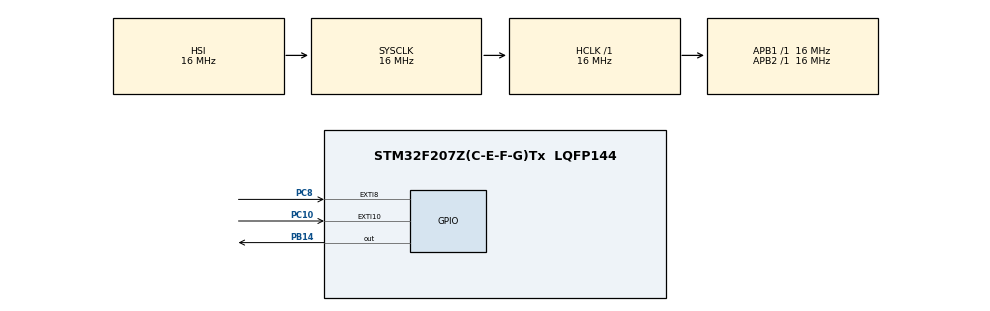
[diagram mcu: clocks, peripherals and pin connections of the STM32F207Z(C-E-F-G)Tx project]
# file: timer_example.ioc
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Mcu.Family=STM32F2
Mcu.Name=STM32F207Z(C-E-F-G)Tx
Mcu.Package=LQFP144
NVIC.EXTI15_10_IRQn=true\:0\:0\:false\:false\:true\:true\:true\:true
NVIC.EXTI9_5_IRQn=true\:0\:0\:false\:false\:true\:true\:true\:true
NVIC.PriorityGroup=NVIC_PRIORITYGROUP_4
NVIC.TIM1_CC_IRQn=true\:0\:0\:false\:false\:true\:true\:true\:true
NVIC.TIM1_UP_TIM10_IRQn=true\:0\:0\:false\:false\:true\:true\:true\:true
PB14.Signal=GPIO_Output
PC10.GPIO_ModeDefaultEXTI=GPIO_MODE_IT_FALLING
PC10.GPIO_PuPd=GPIO_PULLDOWN
PC10.Signal=GPXTI10
PC8.GPIO_ModeDefaultEXTI=GPIO_MODE_IT_RISING
PC8.GPIO_PuPd=GPIO_PULLDOWN
PC8.Signal=GPXTI8
ProjectManager.HeapSize=0x200
ProjectManager.StackSize=0x400
ProjectManager.TargetToolchain=STM32CubeIDE
RCC.48MHZClocksFreq_Value=48000000
RCC.AHBFreq_Value=16000000
RCC.APB1Freq_Value=16000000
RCC.APB2Freq_Value=16000000
RCC.CortexFreq_Value=16000000
RCC.HSE_VALUE=25000000
RCC.HSI_VALUE=16000000
RCC.LSE_VALUE=32768
RCC.SYSCLKFreq_VALUE=16000000
RCC.VCOOutputFreq_Value=192000000
TIM1.Period=10000 - 1
TIM1.Prescaler=1600 - 1
VP_TIM1_VS_ClockSourceINT.Mode=Internal
board=custom

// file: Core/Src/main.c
/* USER CODE BEGIN Header */
/**
  ******************************************************************************
  * @file           : main.c
  * @brief          : Main program body
  ******************************************************************************
  * @attention
  *
  * Copyright (c) 2023 STMicroelectronics.
  * All rights reserved.
  *
  * This software is licensed under terms that can be found in the LICENSE file
  * in the root directory of this software component.
  * If no LICENSE file comes with this software, it is provided AS-IS.
  *
  ******************************************************************************
  */
/* USER CODE END Header */
#include "main.h"

TIM_HandleTypeDef htim1;

void SystemClock_Config(void);
static void MX_GPIO_Init(void);
static void MX_TIM1_Init(void);

/* USER CODE BEGIN 0 */
void HAL_TIM_PeriodElapsedCallback(TIM_HandleTypeDef *htim)
{
	HAL_GPIO_TogglePin(GPIOB, GPIO_PIN_14);
}
void HAL_GPIO_EXTI_Callback(uint16_t GPIO_Pin)
{
	int x = htim1.Instance->ARR;
	if (GPIO_Pin == GPIO_PIN_8)
		{
			if (x + 5000 <= 30000 - 1)
			{
				x = x + 5000;
			}
		}
		if (GPIO_Pin == GPIO_PIN_10)
		{
			if (x - 5000 >= 5000 - 1)
			{
				x = x - 5000;
			}
		}
	htim1.Instance->ARR = x;
}
/* USER CODE END 0 */

int main(void)
{

  /* MCU Configuration--------------------------------------------------------*/

  /* Reset of all peripherals, Initializes the Flash interface and the Systick. */
  HAL_Init();

  /* Configure the system clock */
  SystemClock_Config();

  /* Initialize all configured peripherals */
  MX_GPIO_Init();
  MX_TIM1_Init();
  /* USER CODE BEGIN 2 */
if (__HAL_TIM_GET_FLAG(&htim1, TIM_FLAG_UPDATE) != RESET)
__HAL_TIM_CLEAR_FLAG(&htim1, TIM_FLAG_UPDATE);
HAL_TIM_Base_Start_IT(&htim1);
  /* USER CODE END 2 */

  /* Infinite loop */
  /* USER CODE BEGIN WHILE */
  while (1)
  {
	  int x = htim1.Instance->ARR;
    /* USER CODE END WHILE */

  }
}

void SystemClock_Config(void)
{
  RCC_OscInitTypeDef RCC_OscInitStruct = {0};
  RCC_ClkInitTypeDef RCC_ClkInitStruct = {0};

  /** Initializes the RCC Oscillators according to the specified parameters
  * in the RCC_OscInitTypeDef structure.
  */
  RCC_OscInitStruct.OscillatorType = RCC_OSCILLATORTYPE_HSI;
  RCC_OscInitStruct.HSIState = RCC_HSI_ON;
  RCC_OscInitStruct.HSICalibrationValue = RCC_HSICALIBRATION_DEFAULT;
  RCC_OscInitStruct.PLL.PLLState = RCC_PLL_NONE;
  if (HAL_RCC_OscConfig(&RCC_OscInitStruct) != HAL_OK)
  {
    Error_Handler();
  }

  /** Initializes the CPU, AHB and APB buses clocks
  */
  RCC_ClkInitStruct.ClockType = RCC_CLOCKTYPE_HCLK|RCC_CLOCKTYPE_SYSCLK
                              |RCC_CLOCKTYPE_PCLK1|RCC_CLOCKTYPE_PCLK2;
  RCC_ClkInitStruct.SYSCLKSource = RCC_SYSCLKSOURCE_HSI;
  RCC_ClkInitStruct.AHBCLKDivider = RCC_SYSCLK_DIV1;
  RCC_ClkInitStruct.APB1CLKDivider = RCC_HCLK_DIV1;
  RCC_ClkInitStruct.APB2CLKDivider = RCC_HCLK_DIV1;

  if (HAL_RCC_ClockConfig(&RCC_ClkInitStruct, FLASH_LATENCY_0) != HAL_OK)
  {
    Error_Handler();
  }
}

static void MX_TIM1_Init(void)
{

  TIM_ClockConfigTypeDef sClockSourceConfig = {0};
  TIM_MasterConfigTypeDef sMasterConfig = {0};

  htim1.Instance = TIM1;
  htim1.Init.Prescaler = 1600 - 1;
  htim1.Init.CounterMode = TIM_COUNTERMODE_UP;
  htim1.Init.Period = 10000 - 1;
  htim1.Init.ClockDivision = TIM_CLOCKDIVISION_DIV1;
  htim1.Init.RepetitionCounter = 0;
  htim1.Init.AutoReloadPreload = TIM_AUTORELOAD_PRELOAD_DISABLE;
  if (HAL_TIM_Base_Init(&htim1) != HAL_OK)
  {
    Error_Handler();
  }
  sClockSourceConfig.ClockSource = TIM_CLOCKSOURCE_INTERNAL;
  if (HAL_TIM_ConfigClockSource(&htim1, &sClockSourceConfig) != HAL_OK)
  {
    Error_Handler();
  }
  sMasterConfig.MasterOutputTrigger = TIM_TRGO_RESET;
  sMasterConfig.MasterSlaveMode = TIM_MASTERSLAVEMODE_DISABLE;
  if (HAL_TIMEx_MasterConfigSynchronization(&htim1, &sMasterConfig) != HAL_OK)
  {
    Error_Handler();
  }

}

static void MX_GPIO_Init(void)
{
  GPIO_InitTypeDef GPIO_InitStruct = {0};

  /* GPIO Ports Clock Enable */
  __HAL_RCC_GPIOB_CLK_ENABLE();
  __HAL_RCC_GPIOC_CLK_ENABLE();

  /*Configure GPIO pin Output Level */
  HAL_GPIO_WritePin(GPIOB, GPIO_PIN_14, GPIO_PIN_RESET);

  /*Configure GPIO pin : PB14 */
  GPIO_InitStruct.Pin = GPIO_PIN_14;
  GPIO_InitStruct.Mode = GPIO_MODE_OUTPUT_PP;
  GPIO_InitStruct.Pull = GPIO_NOPULL;
  GPIO_InitStruct.Speed = GPIO_SPEED_FREQ_LOW;
  HAL_GPIO_Init(GPIOB, &GPIO_InitStruct);

  /*Configure GPIO pin : PC8 */
  GPIO_InitStruct.Pin = GPIO_PIN_8;
  GPIO_InitStruct.Mode = GPIO_MODE_IT_RISING;
  GPIO_InitStruct.Pull = GPIO_PULLDOWN;
  HAL_GPIO_Init(GPIOC, &GPIO_InitStruct);

  /*Configure GPIO pin : PC10 */
  GPIO_InitStruct.Pin = GPIO_PIN_10;
  GPIO_InitStruct.Mode = GPIO_MODE_IT_FALLING;
  GPIO_InitStruct.Pull = GPIO_PULLDOWN;
  HAL_GPIO_Init(GPIOC, &GPIO_InitStruct);

  /* EXTI interrupt init*/
  HAL_NVIC_SetPriority(EXTI9_5_IRQn, 0, 0);
  HAL_NVIC_EnableIRQ(EXTI9_5_IRQn);

  HAL_NVIC_SetPriority(EXTI15_10_IRQn, 0, 0);
  HAL_NVIC_EnableIRQ(EXTI15_10_IRQn);

}

void Error_Handler(void)
{
  __disable_irq();
  while (1)
  {
  }
}
